# ESP32-P4 register map
Vendor: ESPRESSIF SYSTEMS (SHANGHAI) CO., LTD.; Series: ESP32 P-Series; File version: 2
CPU: RV32IMAFC r0p0, little endian, no MPU, FPU, 0 interrupt priority bits
Address unit: 32 bits
Registers are 32-bit, read-write, reset 0x0 unless marked. A register's access mark holds for its fields unless they carry their own. Offsets are from the block's base; [hi:lo] are bit positions; {n}, {i} and the like mark numbered series.

## MIPI_DSI_HOST — MIPI Display Interface Host
Base 0x500A0000
0x00 VERSION ro reset 0x3134312A
0x04 PWR_UP
  [0] SHUTDOWNZ
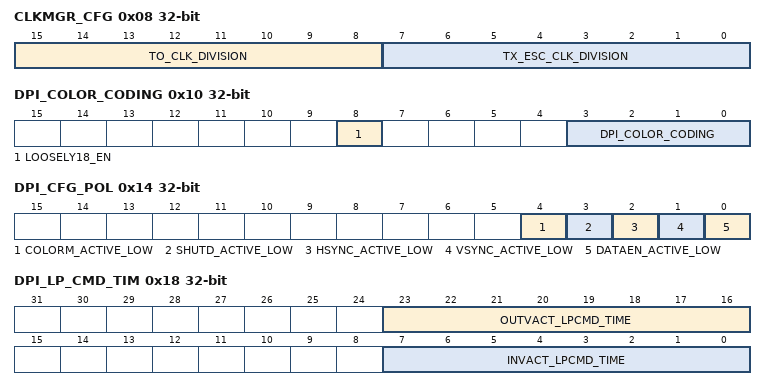
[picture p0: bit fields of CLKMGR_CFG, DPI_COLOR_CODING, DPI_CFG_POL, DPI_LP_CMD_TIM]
0x08 CLKMGR_CFG
  [15:8] TO_CLK_DIVISION, [7:0] TX_ESC_CLK_DIVISION
0x0C DPI_VCID
  [1:0] DPI_VCID
0x10 DPI_COLOR_CODING
  [8] LOOSELY18_EN, [3:0] DPI_COLOR_CODING
0x14 DPI_CFG_POL
  [4] COLORM_ACTIVE_LOW, [3] SHUTD_ACTIVE_LOW, [2] HSYNC_ACTIVE_LOW, [1] VSYNC_ACTIVE_LOW, [0] DATAEN_ACTIVE_LOW
0x18 DPI_LP_CMD_TIM
  [23:16] OUTVACT_LPCMD_TIME, [7:0] INVACT_LPCMD_TIME
0x1C DBI_VCID
  [1:0] DBI_VCID
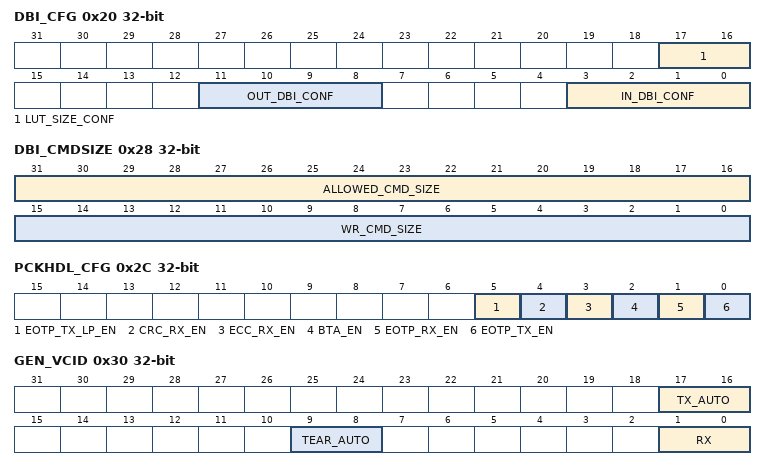
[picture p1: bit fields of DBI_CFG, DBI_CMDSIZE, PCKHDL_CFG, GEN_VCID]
0x20 DBI_CFG
  [17:16] LUT_SIZE_CONF, [11:8] OUT_DBI_CONF, [3:0] IN_DBI_CONF
0x24 DBI_PARTITIONING_EN
  [0] PARTITIONING_EN
0x28 DBI_CMDSIZE
  [31:16] ALLOWED_CMD_SIZE, [15:0] WR_CMD_SIZE
0x2C PCKHDL_CFG
  [5] EOTP_TX_LP_EN, [4] CRC_RX_EN, [3] ECC_RX_EN, [2] BTA_EN, [1] EOTP_RX_EN, [0] EOTP_TX_EN
0x30 GEN_VCID
  [17:16] TX_AUTO, [9:8] TEAR_AUTO, [1:0] RX
0x34 MODE_CFG reset 0x1
  [0] CMD_VIDEO_MODE
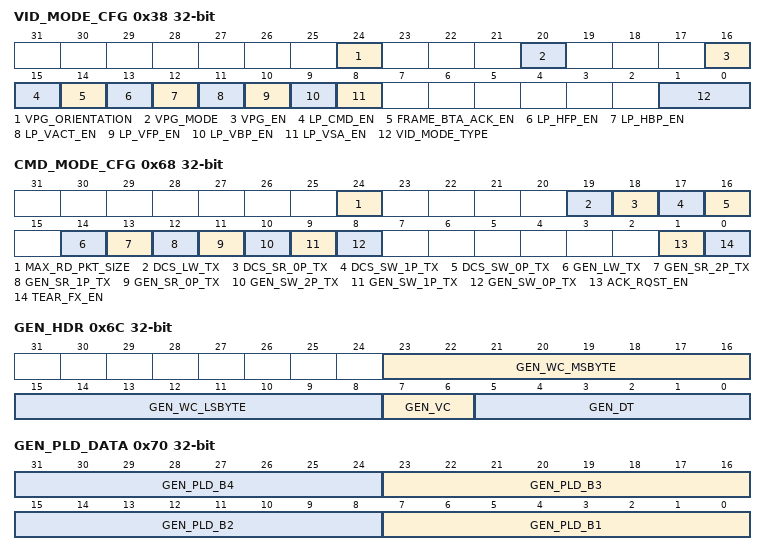
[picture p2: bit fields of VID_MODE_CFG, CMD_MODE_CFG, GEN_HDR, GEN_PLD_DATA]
0x38 VID_MODE_CFG
  [24] VPG_ORIENTATION, [20] VPG_MODE, [16] VPG_EN, [15] LP_CMD_EN, [14] FRAME_BTA_ACK_EN, [13] LP_HFP_EN, [12] LP_HBP_EN, [11] LP_VACT_EN, [10] LP_VFP_EN, [9] LP_VBP_EN, [8] LP_VSA_EN, [1:0] VID_MODE_TYPE
0x3C VID_PKT_SIZE
  [13:0] VID_PKT_SIZE
0x40 VID_NUM_CHUNKS
  [12:0] VID_NUM_CHUNKS
0x44 VID_NULL_SIZE
  [12:0] VID_NULL_SIZE
0x48 VID_HSA_TIME
  [11:0] VID_HSA_TIME
0x4C VID_HBP_TIME
  [11:0] VID_HBP_TIME
0x50 VID_HLINE_TIME
  [14:0] VID_HLINE_TIME
0x54 VID_VSA_LINES
  [9:0] VSA_LINES
0x58 VID_VBP_LINES
  [9:0] VBP_LINES
0x5C VID_VFP_LINES
  [9:0] VFP_LINES
0x60 VID_VACTIVE_LINES
  [13:0] V_ACTIVE_LINES
0x64 EDPI_CMD_SIZE
  [15:0] EDPI_ALLOWED_CMD_SIZE
0x68 CMD_MODE_CFG
  [24] MAX_RD_PKT_SIZE, [19] DCS_LW_TX, [18] DCS_SR_0P_TX, [17] DCS_SW_1P_TX, [16] DCS_SW_0P_TX, [14] GEN_LW_TX, [13] GEN_SR_2P_TX, [12] GEN_SR_1P_TX, [11] GEN_SR_0P_TX, [10] GEN_SW_2P_TX, [9] GEN_SW_1P_TX, [8] GEN_SW_0P_TX, [1] ACK_RQST_EN, [0] TEAR_FX_EN
0x6C GEN_HDR
  [23:16] GEN_WC_MSBYTE, [15:8] GEN_WC_LSBYTE, [7:6] GEN_VC, [5:0] GEN_DT
0x70 GEN_PLD_DATA
  [8n-1:8n-8] GEN_PLD_B{n} (n=1..4)
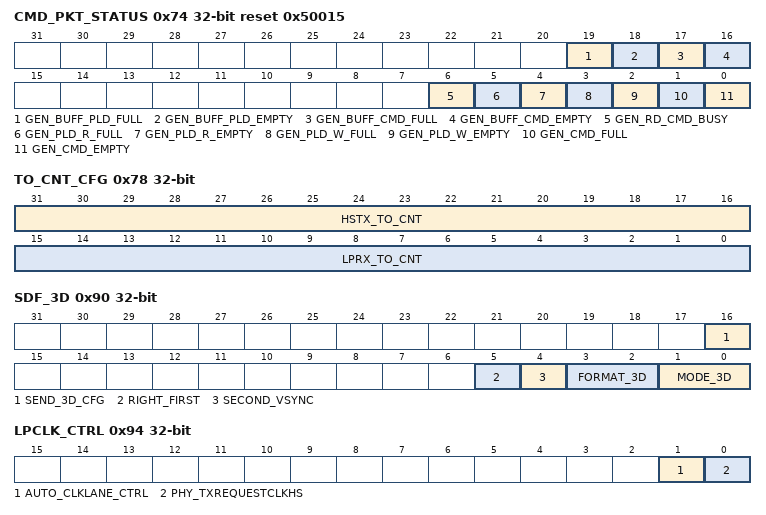
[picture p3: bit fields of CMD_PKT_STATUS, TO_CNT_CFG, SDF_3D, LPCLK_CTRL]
0x74 CMD_PKT_STATUS ro reset 0x50015
  [19] GEN_BUFF_PLD_FULL, [18] GEN_BUFF_PLD_EMPTY, [17] GEN_BUFF_CMD_FULL, [16] GEN_BUFF_CMD_EMPTY, [6] GEN_RD_CMD_BUSY, [5] GEN_PLD_R_FULL, [4] GEN_PLD_R_EMPTY, [3] GEN_PLD_W_FULL, [2] GEN_PLD_W_EMPTY, [1] GEN_CMD_FULL, [0] GEN_CMD_EMPTY
0x78 TO_CNT_CFG
  [31:16] HSTX_TO_CNT, [15:0] LPRX_TO_CNT
0x7C HS_RD_TO_CNT
  [15:0] HS_RD_TO_CNT
0x80 LP_RD_TO_CNT
  [15:0] LP_RD_TO_CNT
0x84 HS_WR_TO_CNT
  [15:0] HS_WR_TO_CNT
0x88 LP_WR_TO_CNT
  [15:0] LP_WR_TO_CNT
0x8C BTA_TO_CNT
  [15:0] BTA_TO_CNT
0x90 SDF_3D
  [16] SEND_3D_CFG, [5] RIGHT_FIRST, [4] SECOND_VSYNC, [3:2] FORMAT_3D, [1:0] MODE_3D
0x94 LPCLK_CTRL
  [1] AUTO_CLKLANE_CTRL, [0] PHY_TXREQUESTCLKHS
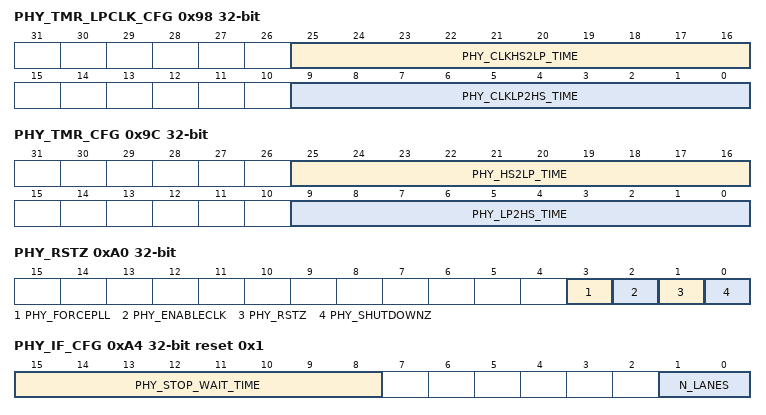
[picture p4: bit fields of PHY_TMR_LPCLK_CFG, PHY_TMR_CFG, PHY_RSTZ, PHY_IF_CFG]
0x98 PHY_TMR_LPCLK_CFG
  [25:16] PHY_CLKHS2LP_TIME, [9:0] PHY_CLKLP2HS_TIME
0x9C PHY_TMR_CFG
  [25:16] PHY_HS2LP_TIME, [9:0] PHY_LP2HS_TIME
0xA0 PHY_RSTZ
  [3] PHY_FORCEPLL, [2] PHY_ENABLECLK, [1] PHY_RSTZ, [0] PHY_SHUTDOWNZ
0xA4 PHY_IF_CFG reset 0x1
  [15:8] PHY_STOP_WAIT_TIME, [1:0] N_LANES
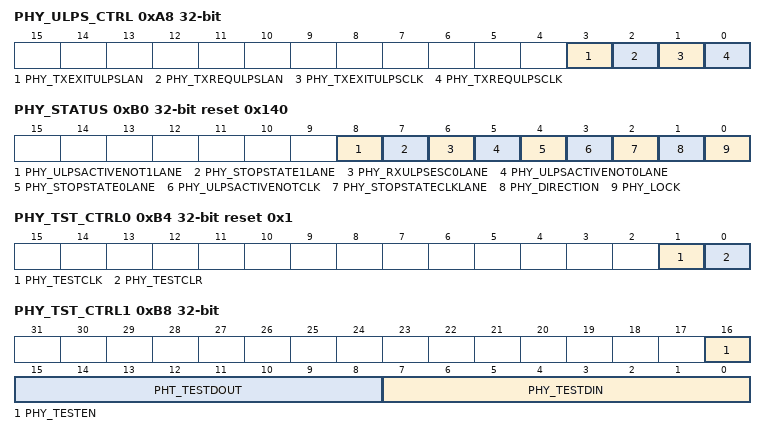
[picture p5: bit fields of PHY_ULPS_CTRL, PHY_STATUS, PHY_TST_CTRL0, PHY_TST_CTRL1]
0xA8 PHY_ULPS_CTRL
  [3] PHY_TXEXITULPSLAN, [2] PHY_TXREQULPSLAN, [1] PHY_TXEXITULPSCLK, [0] PHY_TXREQULPSCLK
0xAC PHY_TX_TRIGGERS
  [3:0] PHY_TX_TRIGGERS
0xB0 PHY_STATUS ro reset 0x140
  [8] PHY_ULPSACTIVENOT1LANE, [7] PHY_STOPSTATE1LANE, [6] PHY_RXULPSESC0LANE, [5] PHY_ULPSACTIVENOT0LANE, [4] PHY_STOPSTATE0LANE, [3] PHY_ULPSACTIVENOTCLK, [2] PHY_STOPSTATECLKLANE, [1] PHY_DIRECTION, [0] PHY_LOCK
0xB4 PHY_TST_CTRL0 reset 0x1
  [1] PHY_TESTCLK, [0] PHY_TESTCLR
0xB8 PHY_TST_CTRL1 access per field
  [16] PHY_TESTEN rw, [15:8] PHT_TESTDOUT ro, [7:0] PHY_TESTDIN rw
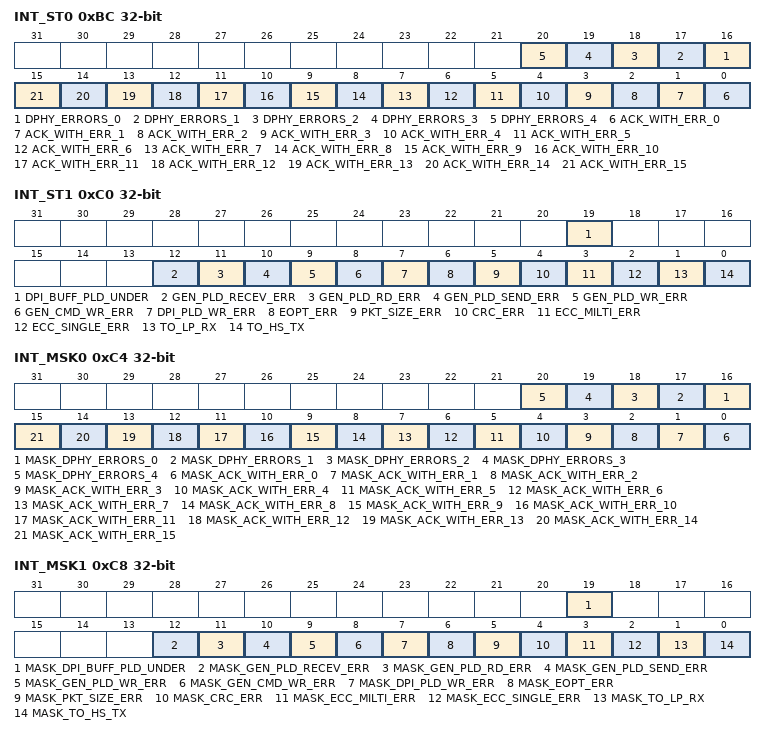
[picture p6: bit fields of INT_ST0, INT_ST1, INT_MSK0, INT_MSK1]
0xBC INT_ST0 ro
  [n+16] DPHY_ERRORS_{n} (n=0..4), [n] ACK_WITH_ERR_{n} (n=0..15)
0xC0 INT_ST1 ro
  [19] DPI_BUFF_PLD_UNDER, [12] GEN_PLD_RECEV_ERR, [11] GEN_PLD_RD_ERR, [10] GEN_PLD_SEND_ERR, [9] GEN_PLD_WR_ERR, [8] GEN_CMD_WR_ERR, [7] DPI_PLD_WR_ERR, [6] EOPT_ERR, [5] PKT_SIZE_ERR, [4] CRC_ERR, [3] ECC_MILTI_ERR, [2] ECC_SINGLE_ERR, [1] TO_LP_RX, [0] TO_HS_TX
0xC4 INT_MSK0
  [n+16] MASK_DPHY_ERRORS_{n} (n=0..4), [n] MASK_ACK_WITH_ERR_{n} (n=0..15)
0xC8 INT_MSK1
  [19] MASK_DPI_BUFF_PLD_UNDER, [12] MASK_GEN_PLD_RECEV_ERR, [11] MASK_GEN_PLD_RD_ERR, [10] MASK_GEN_PLD_SEND_ERR, [9] MASK_GEN_PLD_WR_ERR, [8] MASK_GEN_CMD_WR_ERR, [7] MASK_DPI_PLD_WR_ERR, [6] MASK_EOPT_ERR, [5] MASK_PKT_SIZE_ERR, [4] MASK_CRC_ERR, [3] MASK_ECC_MILTI_ERR, [2] MASK_ECC_SINGLE_ERR, [1] MASK_TO_LP_RX, [0] MASK_TO_HS_TX
0xCC PHY_CAL
  [0] TXSKEWCALHS
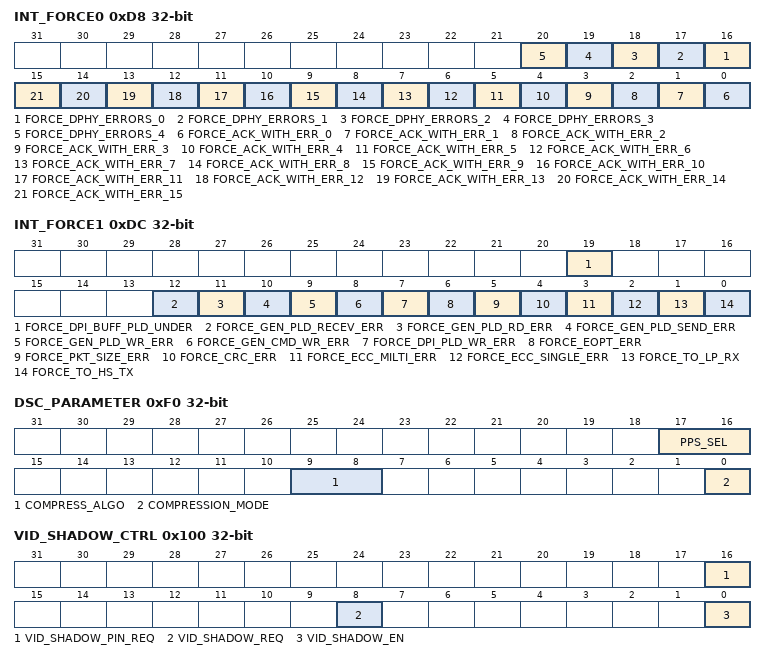
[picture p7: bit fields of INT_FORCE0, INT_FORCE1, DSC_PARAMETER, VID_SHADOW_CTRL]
0xD8 INT_FORCE0
  [n+16] FORCE_DPHY_ERRORS_{n} (n=0..4), [n] FORCE_ACK_WITH_ERR_{n} (n=0..15)
0xDC INT_FORCE1
  [19] FORCE_DPI_BUFF_PLD_UNDER, [12] FORCE_GEN_PLD_RECEV_ERR, [11] FORCE_GEN_PLD_RD_ERR, [10] FORCE_GEN_PLD_SEND_ERR, [9] FORCE_GEN_PLD_WR_ERR, [8] FORCE_GEN_CMD_WR_ERR, [7] FORCE_DPI_PLD_WR_ERR, [6] FORCE_EOPT_ERR, [5] FORCE_PKT_SIZE_ERR, [4] FORCE_CRC_ERR, [3] FORCE_ECC_MILTI_ERR, [2] FORCE_ECC_SINGLE_ERR, [1] FORCE_TO_LP_RX, [0] FORCE_TO_HS_TX
0xF0 DSC_PARAMETER
  [17:16] PPS_SEL, [9:8] COMPRESS_ALGO, [0] COMPRESSION_MODE
0xF4 PHY_TMR_RD_CFG
  [14:0] MAX_RD_TIME
0x100 VID_SHADOW_CTRL
  [16] VID_SHADOW_PIN_REQ, [8] VID_SHADOW_REQ, [0] VID_SHADOW_EN
0x10C DPI_VCID_ACT ro
  [1:0] DPI_VCID_ACT
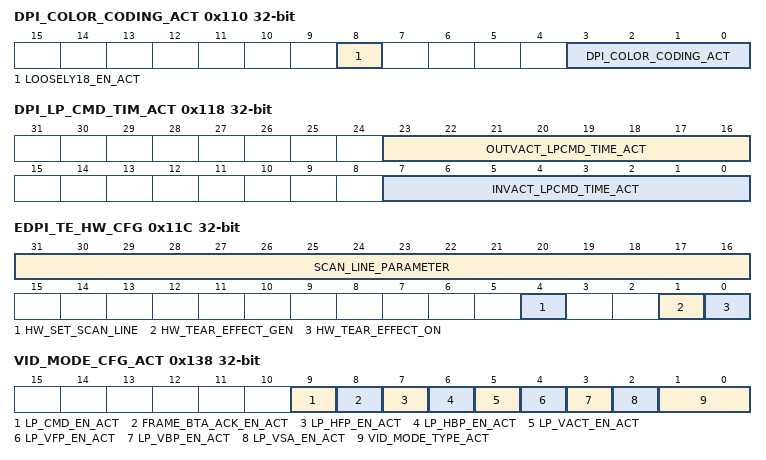
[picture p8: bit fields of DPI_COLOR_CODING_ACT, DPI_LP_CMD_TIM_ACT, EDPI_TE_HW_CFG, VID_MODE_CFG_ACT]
0x110 DPI_COLOR_CODING_ACT ro
  [8] LOOSELY18_EN_ACT, [3:0] DPI_COLOR_CODING_ACT
0x118 DPI_LP_CMD_TIM_ACT ro
  [23:16] OUTVACT_LPCMD_TIME_ACT, [7:0] INVACT_LPCMD_TIME_ACT
0x11C EDPI_TE_HW_CFG
  [31:16] SCAN_LINE_PARAMETER, [4] HW_SET_SCAN_LINE, [1] HW_TEAR_EFFECT_GEN, [0] HW_TEAR_EFFECT_ON
0x138 VID_MODE_CFG_ACT ro
  [9] LP_CMD_EN_ACT, [8] FRAME_BTA_ACK_EN_ACT, [7] LP_HFP_EN_ACT, [6] LP_HBP_EN_ACT, [5] LP_VACT_EN_ACT, [4] LP_VFP_EN_ACT, [3] LP_VBP_EN_ACT, [2] LP_VSA_EN_ACT, [1:0] VID_MODE_TYPE_ACT
0x13C VID_PKT_SIZE_ACT ro
  [13:0] VID_PKT_SIZE_ACT
0x140 VID_NUM_CHUNKS_ACT ro
  [12:0] VID_NUM_CHUNKS_ACT
0x144 VID_NULL_SIZE_ACT ro
  [12:0] VID_NULL_SIZE_ACT
0x148 VID_HSA_TIME_ACT ro
  [11:0] VID_HSA_TIME_ACT
0x14C VID_HBP_TIME_ACT ro
  [11:0] VID_HBP_TIME_ACT
0x150 VID_HLINE_TIME_ACT ro
  [14:0] VID_HLINE_TIME_ACT
0x154 VID_VSA_LINES_ACT ro
  [9:0] VSA_LINES_ACT
0x158 VID_VBP_LINES_ACT ro
  [9:0] VBP_LINES_ACT
0x15C VID_VFP_LINES_ACT ro
  [9:0] VFP_LINES_ACT
0x160 VID_VACTIVE_LINES_ACT ro
  [13:0] V_ACTIVE_LINES_ACT
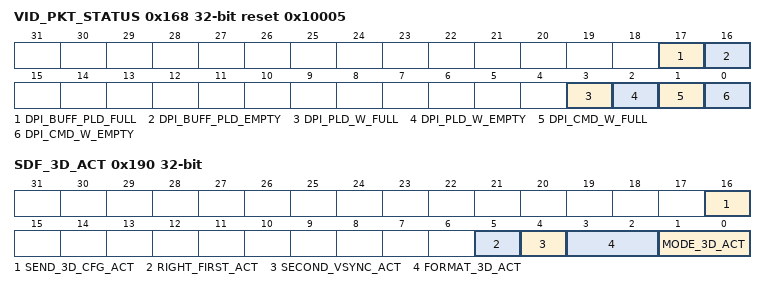
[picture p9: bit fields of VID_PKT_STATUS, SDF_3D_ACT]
0x168 VID_PKT_STATUS ro reset 0x10005
  [17] DPI_BUFF_PLD_FULL, [16] DPI_BUFF_PLD_EMPTY, [3] DPI_PLD_W_FULL, [2] DPI_PLD_W_EMPTY, [1] DPI_CMD_W_FULL, [0] DPI_CMD_W_EMPTY
0x190 SDF_3D_ACT ro
  [16] SEND_3D_CFG_ACT, [5] RIGHT_FIRST_ACT, [4] SECOND_VSYNC_ACT, [3:2] FORMAT_3D_ACT, [1:0] MODE_3D_ACT
